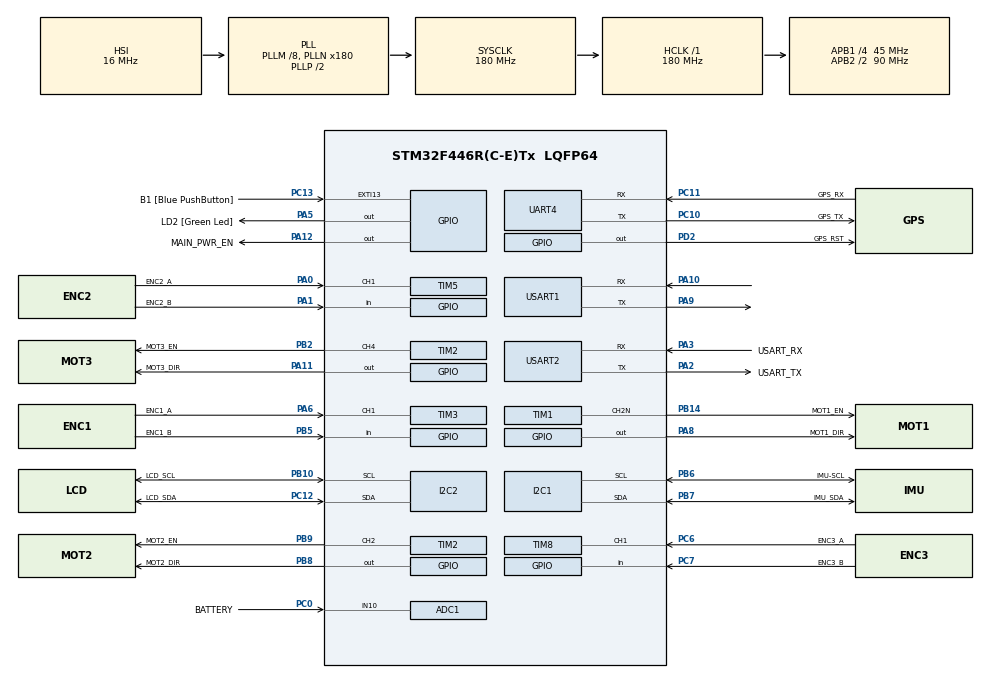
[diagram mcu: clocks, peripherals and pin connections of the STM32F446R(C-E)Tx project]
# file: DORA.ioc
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ADC1.Channel-0\#ChannelRegularConversion=ADC_CHANNEL_10
ADC1.InjNumberOfConversion=0
ADC1.NbrOfConversionFlag=1
ADC1.Rank-0\#ChannelRegularConversion=1
ADC1.SamplingTime-0\#ChannelRegularConversion=ADC_SAMPLETIME_3CYCLES
ADC1.master=1
Dma.Request0=USART2_TX
Dma.Request1=USART2_RX
Dma.Request2=USART1_RX
Dma.Request3=USART1_TX
Dma.USART1_RX.2.Direction=DMA_PERIPH_TO_MEMORY
Dma.USART1_RX.2.FIFOMode=DMA_FIFOMODE_DISABLE
Dma.USART1_RX.2.Instance=DMA2_Stream2
Dma.USART1_RX.2.MemDataAlignment=DMA_MDATAALIGN_BYTE
Dma.USART1_RX.2.MemInc=DMA_MINC_ENABLE
Dma.USART1_RX.2.Mode=DMA_CIRCULAR
Dma.USART1_RX.2.PeriphDataAlignment=DMA_PDATAALIGN_BYTE
Dma.USART1_RX.2.PeriphInc=DMA_PINC_DISABLE
Dma.USART1_RX.2.Priority=DMA_PRIORITY_LOW
Dma.USART1_TX.3.Direction=DMA_MEMORY_TO_PERIPH
Dma.USART1_TX.3.FIFOMode=DMA_FIFOMODE_DISABLE
Dma.USART1_TX.3.Instance=DMA2_Stream7
Dma.USART1_TX.3.MemDataAlignment=DMA_MDATAALIGN_BYTE
Dma.USART1_TX.3.MemInc=DMA_MINC_ENABLE
Dma.USART1_TX.3.Mode=DMA_NORMAL
Dma.USART1_TX.3.PeriphDataAlignment=DMA_PDATAALIGN_BYTE
Dma.USART1_TX.3.PeriphInc=DMA_PINC_DISABLE
Dma.USART1_TX.3.Priority=DMA_PRIORITY_LOW
Dma.USART2_RX.1.Direction=DMA_PERIPH_TO_MEMORY
Dma.USART2_RX.1.FIFOMode=DMA_FIFOMODE_DISABLE
Dma.USART2_RX.1.Instance=DMA1_Stream5
Dma.USART2_RX.1.MemDataAlignment=DMA_MDATAALIGN_BYTE
Dma.USART2_RX.1.MemInc=DMA_MINC_ENABLE
Dma.USART2_RX.1.Mode=DMA_CIRCULAR
Dma.USART2_RX.1.PeriphDataAlignment=DMA_PDATAALIGN_BYTE
Dma.USART2_RX.1.PeriphInc=DMA_PINC_DISABLE
Dma.USART2_RX.1.Priority=DMA_PRIORITY_LOW
Dma.USART2_TX.0.Direction=DMA_MEMORY_TO_PERIPH
Dma.USART2_TX.0.FIFOMode=DMA_FIFOMODE_DISABLE
Dma.USART2_TX.0.Instance=DMA1_Stream6
Dma.USART2_TX.0.MemDataAlignment=DMA_MDATAALIGN_BYTE
Dma.USART2_TX.0.MemInc=DMA_MINC_ENABLE
Dma.USART2_TX.0.Mode=DMA_NORMAL
Dma.USART2_TX.0.PeriphDataAlignment=DMA_PDATAALIGN_BYTE
Dma.USART2_TX.0.PeriphInc=DMA_PINC_DISABLE
Dma.USART2_TX.0.Priority=DMA_PRIORITY_LOW
I2C2.I2C_Mode=I2C_Fast
Mcu.Family=STM32F4
Mcu.Name=STM32F446R(C-E)Tx
Mcu.Package=LQFP64
NVIC.ADC_IRQn=true\:0\:8\:false\:false\:true\:true\:true\:true
NVIC.DMA1_Stream5_IRQn=true\:0\:0\:false\:false\:true\:false\:true\:true
NVIC.DMA1_Stream6_IRQn=true\:0\:0\:false\:false\:true\:false\:true\:true
NVIC.DMA2_Stream2_IRQn=true\:0\:0\:false\:false\:true\:false\:true\:true
NVIC.DMA2_Stream7_IRQn=true\:0\:0\:false\:false\:true\:false\:true\:true
NVIC.I2C2_EV_IRQn=true\:0\:0\:false\:false\:true\:true\:true\:true
NVIC.PriorityGroup=NVIC_PRIORITYGROUP_0
NVIC.TIM1_UP_TIM10_IRQn=true\:0\:0\:false\:false\:true\:true\:true\:true
NVIC.TIM2_IRQn=true\:0\:0\:false\:false\:true\:true\:true\:true
NVIC.TIM3_IRQn=true\:0\:0\:false\:false\:true\:true\:true\:true
NVIC.TIM5_IRQn=true\:0\:0\:false\:false\:true\:true\:true\:true
NVIC.TIM6_DAC_IRQn=true\:0\:10\:false\:false\:true\:true\:true\:true
NVIC.TIM8_CC_IRQn=true\:0\:0\:false\:false\:true\:true\:true\:true
NVIC.TIM8_UP_TIM13_IRQn=true\:0\:0\:false\:false\:true\:true\:true\:true
NVIC.UART4_IRQn=true\:0\:0\:false\:false\:true\:true\:true\:true
NVIC.USART1_IRQn=true\:0\:0\:false\:false\:true\:true\:true\:true
NVIC.USART2_IRQn=true\:0\:0\:false\:false\:true\:true\:true\:true
PA0-WKUP.GPIO_Label=ENC2_A
PA0-WKUP.Signal=S_TIM5_CH1
PA1.GPIO_Label=ENC2_B
PA1.Signal=GPIO_Input
PA10.Mode=Asynchronous
PA10.Signal=USART1_RX
PA11.GPIO_Label=MOT3_DIR
PA11.Signal=GPIO_Output
PA12.GPIO_Label=MAIN_PWR_EN
PA12.Signal=GPIO_Output
PA13.GPIO_Label=TMS
PA13.Mode=Serial_Wire
PA13.Signal=SYS_JTMS-SWDIO
PA14.GPIO_Label=TCK
PA14.Mode=Serial_Wire
PA14.Signal=SYS_JTCK-SWCLK
PA2.GPIO_Label=USART_TX
PA2.Mode=Asynchronous
PA2.Signal=USART2_TX
PA3.GPIO_Label=USART_RX
PA3.Mode=Asynchronous
PA3.Signal=USART2_RX
PA5.GPIO_Label=LD2 [Green Led]
PA5.Signal=GPIO_Output
PA6.GPIO_Label=ENC1_A
PA6.Signal=S_TIM3_CH1
PA8.GPIO_Label=MOT1_DIR
PA8.Signal=GPIO_Output
PA9.Mode=Asynchronous
PA9.Signal=USART1_TX
PB10.GPIO_Label=LCD_SCL
PB10.Mode=I2C
PB10.Signal=I2C2_SCL
PB14.GPIO_Label=MOT1_EN
PB14.Mode=PWM Generation2 CH2N
PB14.Signal=TIM1_CH2N
PB2.GPIO_Label=MOT3_EN
PB2.Signal=S_TIM2_CH4
PB3.GPIO_Label=SWO
PB3.Signal=SYS_JTDO-SWO
PB5.GPIO_Label=ENC1_B
PB5.Signal=GPIO_Input
PB6.GPIO_Label=IMU-SCL
PB6.Mode=I2C
PB6.Signal=I2C1_SCL
PB7.GPIO_Label=IMU_SDA
PB7.Mode=I2C
PB7.Signal=I2C1_SDA
PB8.GPIO_Label=MOT2_DIR
PB8.Signal=GPIO_Output
PB9.GPIO_Label=MOT2_EN
PB9.Signal=S_TIM2_CH2
PC0.GPIO_Label=BATTERY
PC0.Signal=ADCx_IN10
PC10.GPIO_Label=GPS_TX
PC10.Mode=Asynchronous
PC10.Signal=UART4_TX
PC11.GPIO_Label=GPS_RX
PC11.Mode=Asynchronous
PC11.Signal=UART4_RX
PC12.GPIO_Label=LCD_SDA
PC12.Mode=I2C
PC12.Signal=I2C2_SDA
PC13.GPIO_Label=B1 [Blue PushButton]
PC13.GPIO_ModeDefaultEXTI=GPIO_MODE_IT_FALLING
PC13.Signal=GPXTI13
PC14-OSC32_IN.Mode=LSE-External-Oscillator
PC14-OSC32_IN.Signal=RCC_OSC32_IN
PC15-OSC32_OUT.Mode=LSE-External-Oscillator
PC15-OSC32_OUT.Signal=RCC_OSC32_OUT
PC6.GPIO_Label=ENC3_A
PC6.Signal=S_TIM8_CH1
PC7.GPIO_Label=ENC3_B
PC7.Signal=GPIO_Input
PD2.GPIO_Label=GPS_RST
PD2.Signal=GPIO_Output
PH0-OSC_IN.Mode=HSE-External-Oscillator
PH0-OSC_IN.Signal=RCC_OSC_IN
PH1-OSC_OUT.Mode=HSE-External-Oscillator
PH1-OSC_OUT.Signal=RCC_OSC_OUT
ProjectManager.HeapSize=0x200
ProjectManager.StackSize=0x400
ProjectManager.TargetToolchain=STM32CubeIDE
RCC.48MHZClocksFreq_Value=84000000
RCC.AHBFreq_Value=180000000
RCC.APB1CLKDivider=RCC_HCLK_DIV4
RCC.APB1Freq_Value=45000000
RCC.APB1TimFreq_Value=90000000
RCC.APB2CLKDivider=RCC_HCLK_DIV2
RCC.APB2Freq_Value=90000000
RCC.APB2TimFreq_Value=180000000
RCC.CortexFreq_Value=180000000
RCC.FLatency-AdvancedSettings=FLASH_LATENCY_5
RCC.HCLKFreq_Value=180000000
RCC.HSE_VALUE=8000000
RCC.HSI_VALUE=16000000
RCC.PLLM=8
RCC.PLLN=180
RCC.SYSCLKFreq_VALUE=180000000
RCC.SYSCLKSource=RCC_SYSCLKSOURCE_PLLCLK
RCC.USBFreq_Value=180000000
RCC.VCOOutputFreq_Value=360000000
SH.ADCx_IN10.0=ADC1_IN10,IN10
SH.S_TIM2_CH2.0=TIM2_CH2,PWM Generation2 CH2
SH.S_TIM2_CH4.0=TIM2_CH4,PWM Generation4 CH4
SH.S_TIM3_CH1.0=TIM3_CH1,Input_Capture1_from_TI1
SH.S_TIM5_CH1.0=TIM5_CH1,Input_Capture1_from_TI1
SH.S_TIM8_CH1.0=TIM8_CH1,Input_Capture1_from_TI1
TIM1.AutoReloadPreload=TIM_AUTORELOAD_PRELOAD_ENABLE
TIM1.Channel-PWM\ Generation2\ CH2N=TIM_CHANNEL_2
TIM1.OCNIdleState_2=TIM_OCNIDLESTATE_RESET
TIM1.OCNPolarity_2=TIM_OCNPOLARITY_HIGH
TIM1.Period=1023
TIM1.Prescaler=9
TIM2.AutoReloadPreload=TIM_AUTORELOAD_PRELOAD_ENABLE
TIM2.Channel-PWM\ Generation2\ CH2=TIM_CHANNEL_2
TIM2.Channel-PWM\ Generation4\ CH4=TIM_CHANNEL_4
TIM2.Period=1023
TIM2.Prescaler=4
TIM3.Channel-Input_Capture1_from_TI1=TIM_CHANNEL_1
TIM3.ICFilter_CH1=12
TIM3.ICPolarity_CH1=TIM_INPUTCHANNELPOLARITY_BOTHEDGE
TIM3.Prescaler=3
TIM5.Channel-Input_Capture1_from_TI1=TIM_CHANNEL_1
TIM5.ICFilter_CH1=12
TIM5.ICPolarity_CH1=TIM_INPUTCHANNELPOLARITY_BOTHEDGE
TIM5.Period=65535
TIM5.Prescaler=3
TIM6.Period=999
TIM6.Prescaler=180
TIM8.Channel-Input_Capture1_from_TI1=TIM_CHANNEL_1
TIM8.ClockDivision=TIM_CLOCKDIVISION_DIV1
TIM8.ICFilter_CH1=12
TIM8.ICPolarity_CH1=TIM_INPUTCHANNELPOLARITY_BOTHEDGE
TIM8.Prescaler=7
UART4.VirtualMode=Asynchronous
USART1.VirtualMode=VM_ASYNC
USART2.VirtualMode=VM_ASYNC
VP_TIM1_VS_ClockSourceINT.Mode=Internal
VP_TIM2_VS_ClockSourceINT.Mode=Internal
VP_TIM3_VS_ClockSourceINT.Mode=Internal
VP_TIM5_VS_ClockSourceINT.Mode=Internal
VP_TIM6_VS_ClockSourceINT.Mode=Enable_Timer
VP_TIM8_VS_ClockSourceINT.Mode=Internal
board=NUCLEO-F446RE

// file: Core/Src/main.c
/* USER CODE BEGIN Header */
/**
 ******************************************************************************
 * @file           : main.c
 * @brief          : Main program body
 ******************************************************************************
 * @attention
 *
 * Copyright (c) 2023 STMicroelectronics.
 * All rights reserved.
 *
 * This software is licensed under terms that can be found in the LICENSE file
 * in the root directory of this software component.
 * If no LICENSE file comes with this software, it is provided AS-IS.
 *
 ******************************************************************************
 */
/* USER CODE END Header */
#include "main.h"

/* USER CODE BEGIN Includes */

#include "controlInterface.h"

/* USER CODE END Includes */

ADC_HandleTypeDef hadc1;

I2C_HandleTypeDef hi2c1;
I2C_HandleTypeDef hi2c2;

TIM_HandleTypeDef htim1;
TIM_HandleTypeDef htim2;
TIM_HandleTypeDef htim3;
TIM_HandleTypeDef htim5;
TIM_HandleTypeDef htim6;
TIM_HandleTypeDef htim8;

UART_HandleTypeDef huart4;
UART_HandleTypeDef huart1;
UART_HandleTypeDef huart2;
DMA_HandleTypeDef hdma_usart1_rx;
DMA_HandleTypeDef hdma_usart1_tx;
DMA_HandleTypeDef hdma_usart2_tx;
DMA_HandleTypeDef hdma_usart2_rx;

void SystemClock_Config(void);
static void MX_GPIO_Init(void);
static void MX_DMA_Init(void);
static void MX_USART2_UART_Init(void);
static void MX_ADC1_Init(void);
static void MX_I2C1_Init(void);
static void MX_I2C2_Init(void);
static void MX_TIM1_Init(void);
static void MX_TIM2_Init(void);
static void MX_TIM3_Init(void);
static void MX_TIM5_Init(void);
static void MX_TIM8_Init(void);
static void MX_UART4_Init(void);
static void MX_TIM6_Init(void);
static void MX_USART1_UART_Init(void);

int main(void) {

    /* MCU Configuration--------------------------------------------------------*/

    /* Reset of all peripherals, Initializes the Flash interface and the Systick. */
    HAL_Init();

    /* Configure the system clock */
    SystemClock_Config();

    /* Initialize all configured peripherals */
    MX_GPIO_Init();
    MX_DMA_Init();
    MX_USART2_UART_Init();
    MX_ADC1_Init();
    MX_I2C1_Init();
    MX_I2C2_Init();
    MX_TIM1_Init();
    MX_TIM2_Init();
    MX_TIM3_Init();
    MX_TIM5_Init();
    MX_TIM8_Init();
    MX_UART4_Init();
    MX_TIM6_Init();
    MX_USART1_UART_Init();
    /* USER CODE BEGIN 2 */

    startControl();

    /* USER CODE END 2 */

    /* Infinite loop */
    while (1) {

    }
}

void SystemClock_Config(void) {
    RCC_OscInitTypeDef RCC_OscInitStruct = { 0 };
    RCC_ClkInitTypeDef RCC_ClkInitStruct = { 0 };

    /** Configure the main internal regulator output voltage
     */
    __HAL_RCC_PWR_CLK_ENABLE();
    __HAL_PWR_VOLTAGESCALING_CONFIG(PWR_REGULATOR_VOLTAGE_SCALE1);

    /** Initializes the RCC Oscillators according to the specified parameters
     * in the RCC_OscInitTypeDef structure.
     */
    RCC_OscInitStruct.OscillatorType = RCC_OSCILLATORTYPE_HSI;
    RCC_OscInitStruct.HSIState = RCC_HSI_ON;
    RCC_OscInitStruct.HSICalibrationValue = RCC_HSICALIBRATION_DEFAULT;
    RCC_OscInitStruct.PLL.PLLState = RCC_PLL_ON;
    RCC_OscInitStruct.PLL.PLLSource = RCC_PLLSOURCE_HSI;
    RCC_OscInitStruct.PLL.PLLM = 8;
    RCC_OscInitStruct.PLL.PLLN = 180;
    RCC_OscInitStruct.PLL.PLLP = RCC_PLLP_DIV2;
    RCC_OscInitStruct.PLL.PLLQ = 2;
    RCC_OscInitStruct.PLL.PLLR = 2;
    if (HAL_RCC_OscConfig(&RCC_OscInitStruct) != HAL_OK) {
        Error_Handler();
    }

    /** Activate the Over-Drive mode
     */
    if (HAL_PWREx_EnableOverDrive() != HAL_OK) {
        Error_Handler();
    }

    /** Initializes the CPU, AHB and APB buses clocks
     */
    RCC_ClkInitStruct.ClockType = RCC_CLOCKTYPE_HCLK | RCC_CLOCKTYPE_SYSCLK | RCC_CLOCKTYPE_PCLK1 | RCC_CLOCKTYPE_PCLK2;
    RCC_ClkInitStruct.SYSCLKSource = RCC_SYSCLKSOURCE_PLLCLK;
    RCC_ClkInitStruct.AHBCLKDivider = RCC_SYSCLK_DIV1;
    RCC_ClkInitStruct.APB1CLKDivider = RCC_HCLK_DIV4;
    RCC_ClkInitStruct.APB2CLKDivider = RCC_HCLK_DIV2;

    if (HAL_RCC_ClockConfig(&RCC_ClkInitStruct, FLASH_LATENCY_5) != HAL_OK) {
        Error_Handler();
    }
}

static void MX_ADC1_Init(void) {

    ADC_ChannelConfTypeDef sConfig = { 0 };

    /** Configure the global features of the ADC (Clock, Resolution, Data Alignment and number of conversion)
     */
    hadc1.Instance = ADC1;
    hadc1.Init.ClockPrescaler = ADC_CLOCK_SYNC_PCLK_DIV4;
    hadc1.Init.Resolution = ADC_RESOLUTION_12B;
    hadc1.Init.ScanConvMode = DISABLE;
    hadc1.Init.ContinuousConvMode = DISABLE;
    hadc1.Init.DiscontinuousConvMode = DISABLE;
    hadc1.Init.ExternalTrigConvEdge = ADC_EXTERNALTRIGCONVEDGE_NONE;
    hadc1.Init.ExternalTrigConv = ADC_SOFTWARE_START;
    hadc1.Init.DataAlign = ADC_DATAALIGN_RIGHT;
    hadc1.Init.NbrOfConversion = 1;
    hadc1.Init.DMAContinuousRequests = DISABLE;
    hadc1.Init.EOCSelection = ADC_EOC_SINGLE_CONV;
    if (HAL_ADC_Init(&hadc1) != HAL_OK) {
        Error_Handler();
    }

    /** Configure for the selected ADC regular channel its corresponding rank in the sequencer and its sample time.
     */
    sConfig.Channel = ADC_CHANNEL_10;
    sConfig.Rank = 1;
    sConfig.SamplingTime = ADC_SAMPLETIME_3CYCLES;
    if (HAL_ADC_ConfigChannel(&hadc1, &sConfig) != HAL_OK) {
        Error_Handler();
    }
}

static void MX_I2C1_Init(void) {

    hi2c1.Instance = I2C1;
    hi2c1.Init.ClockSpeed = 100000;
    hi2c1.Init.DutyCycle = I2C_DUTYCYCLE_2;
    hi2c1.Init.OwnAddress1 = 0;
    hi2c1.Init.AddressingMode = I2C_ADDRESSINGMODE_7BIT;
    hi2c1.Init.DualAddressMode = I2C_DUALADDRESS_DISABLE;
    hi2c1.Init.OwnAddress2 = 0;
    hi2c1.Init.GeneralCallMode = I2C_GENERALCALL_DISABLE;
    hi2c1.Init.NoStretchMode = I2C_NOSTRETCH_DISABLE;
    if (HAL_I2C_Init(&hi2c1) != HAL_OK) {
        Error_Handler();
    }
}

static void MX_I2C2_Init(void) {

    hi2c2.Instance = I2C2;
    hi2c2.Init.ClockSpeed = 400000;
    hi2c2.Init.DutyCycle = I2C_DUTYCYCLE_2;
    hi2c2.Init.OwnAddress1 = 0;
    hi2c2.Init.AddressingMode = I2C_ADDRESSINGMODE_7BIT;
    hi2c2.Init.DualAddressMode = I2C_DUALADDRESS_DISABLE;
    hi2c2.Init.OwnAddress2 = 0;
    hi2c2.Init.GeneralCallMode = I2C_GENERALCALL_DISABLE;
    hi2c2.Init.NoStretchMode = I2C_NOSTRETCH_DISABLE;
    if (HAL_I2C_Init(&hi2c2) != HAL_OK) {
        Error_Handler();
    }
}

static void MX_TIM1_Init(void) {

    TIM_ClockConfigTypeDef sClockSourceConfig = { 0 };
    TIM_MasterConfigTypeDef sMasterConfig = { 0 };
    TIM_OC_InitTypeDef sConfigOC = { 0 };
    TIM_BreakDeadTimeConfigTypeDef sBreakDeadTimeConfig = { 0 };

    htim1.Instance = TIM1;
    htim1.Init.Prescaler = 9;
    htim1.Init.CounterMode = TIM_COUNTERMODE_UP;
    htim1.Init.Period = 1023;
    htim1.Init.ClockDivision = TIM_CLOCKDIVISION_DIV1;
    htim1.Init.RepetitionCounter = 0;
    htim1.Init.AutoReloadPreload = TIM_AUTORELOAD_PRELOAD_ENABLE;
    if (HAL_TIM_Base_Init(&htim1) != HAL_OK) {
        Error_Handler();
    }
    sClockSourceConfig.ClockSource = TIM_CLOCKSOURCE_INTERNAL;
    if (HAL_TIM_ConfigClockSource(&htim1, &sClockSourceConfig) != HAL_OK) {
        Error_Handler();
    }
    if (HAL_TIM_PWM_Init(&htim1) != HAL_OK) {
        Error_Handler();
    }
    sMasterConfig.MasterOutputTrigger = TIM_TRGO_RESET;
    sMasterConfig.MasterSlaveMode = TIM_MASTERSLAVEMODE_DISABLE;
    if (HAL_TIMEx_MasterConfigSynchronization(&htim1, &sMasterConfig) != HAL_OK) {
        Error_Handler();
    }
    sConfigOC.OCMode = TIM_OCMODE_PWM1;
    sConfigOC.Pulse = 0;
    sConfigOC.OCPolarity = TIM_OCPOLARITY_HIGH;
    sConfigOC.OCNPolarity = TIM_OCNPOLARITY_HIGH;
    sConfigOC.OCFastMode = TIM_OCFAST_DISABLE;
    sConfigOC.OCIdleState = TIM_OCIDLESTATE_RESET;
    sConfigOC.OCNIdleState = TIM_OCNIDLESTATE_RESET;
    if (HAL_TIM_PWM_ConfigChannel(&htim1, &sConfigOC, TIM_CHANNEL_2) != HAL_OK) {
        Error_Handler();
    }
    sBreakDeadTimeConfig.OffStateRunMode = TIM_OSSR_DISABLE;
    sBreakDeadTimeConfig.OffStateIDLEMode = TIM_OSSI_DISABLE;
    sBreakDeadTimeConfig.LockLevel = TIM_LOCKLEVEL_OFF;
    sBreakDeadTimeConfig.DeadTime = 0;
    sBreakDeadTimeConfig.BreakState = TIM_BREAK_DISABLE;
    sBreakDeadTimeConfig.BreakPolarity = TIM_BREAKPOLARITY_HIGH;
    sBreakDeadTimeConfig.AutomaticOutput = TIM_AUTOMATICOUTPUT_DISABLE;
    if (HAL_TIMEx_ConfigBreakDeadTime(&htim1, &sBreakDeadTimeConfig) != HAL_OK) {
        Error_Handler();
    }
    HAL_TIM_MspPostInit(&htim1);
}

static void MX_TIM2_Init(void) {

    TIM_ClockConfigTypeDef sClockSourceConfig = { 0 };
    TIM_MasterConfigTypeDef sMasterConfig = { 0 };
    TIM_OC_InitTypeDef sConfigOC = { 0 };

    htim2.Instance = TIM2;
    htim2.Init.Prescaler = 4;
    htim2.Init.CounterMode = TIM_COUNTERMODE_UP;
    htim2.Init.Period = 1023;
    htim2.Init.ClockDivision = TIM_CLOCKDIVISION_DIV1;
    htim2.Init.AutoReloadPreload = TIM_AUTORELOAD_PRELOAD_ENABLE;
    if (HAL_TIM_Base_Init(&htim2) != HAL_OK) {
        Error_Handler();
    }
    sClockSourceConfig.ClockSource = TIM_CLOCKSOURCE_INTERNAL;
    if (HAL_TIM_ConfigClockSource(&htim2, &sClockSourceConfig) != HAL_OK) {
        Error_Handler();
    }
    if (HAL_TIM_PWM_Init(&htim2) != HAL_OK) {
        Error_Handler();
    }
    sMasterConfig.MasterOutputTrigger = TIM_TRGO_RESET;
    sMasterConfig.MasterSlaveMode = TIM_MASTERSLAVEMODE_DISABLE;
    if (HAL_TIMEx_MasterConfigSynchronization(&htim2, &sMasterConfig) != HAL_OK) {
        Error_Handler();
    }
    sConfigOC.OCMode = TIM_OCMODE_PWM1;
    sConfigOC.Pulse = 0;
    sConfigOC.OCPolarity = TIM_OCPOLARITY_HIGH;
    sConfigOC.OCFastMode = TIM_OCFAST_DISABLE;
    if (HAL_TIM_PWM_ConfigChannel(&htim2, &sConfigOC, TIM_CHANNEL_2) != HAL_OK) {
        Error_Handler();
    }
    if (HAL_TIM_PWM_ConfigChannel(&htim2, &sConfigOC, TIM_CHANNEL_4) != HAL_OK) {
        Error_Handler();
    }
    HAL_TIM_MspPostInit(&htim2);
}

static void MX_TIM3_Init(void) {

    TIM_ClockConfigTypeDef sClockSourceConfig = { 0 };
    TIM_MasterConfigTypeDef sMasterConfig = { 0 };
    TIM_IC_InitTypeDef sConfigIC = { 0 };

    htim3.Instance = TIM3;
    htim3.Init.Prescaler = 3;
    htim3.Init.CounterMode = TIM_COUNTERMODE_UP;
    htim3.Init.Period = 65535;
    htim3.Init.ClockDivision = TIM_CLOCKDIVISION_DIV1;
    htim3.Init.AutoReloadPreload = TIM_AUTORELOAD_PRELOAD_DISABLE;
    if (HAL_TIM_Base_Init(&htim3) != HAL_OK) {
        Error_Handler();
    }
    sClockSourceConfig.ClockSource = TIM_CLOCKSOURCE_INTERNAL;
    if (HAL_TIM_ConfigClockSource(&htim3, &sClockSourceConfig) != HAL_OK) {
        Error_Handler();
    }
    if (HAL_TIM_IC_Init(&htim3) != HAL_OK) {
        Error_Handler();
    }
    sMasterConfig.MasterOutputTrigger = TIM_TRGO_RESET;
    sMasterConfig.MasterSlaveMode = TIM_MASTERSLAVEMODE_DISABLE;
    if (HAL_TIMEx_MasterConfigSynchronization(&htim3, &sMasterConfig) != HAL_OK) {
        Error_Handler();
    }
    sConfigIC.ICPolarity = TIM_INPUTCHANNELPOLARITY_BOTHEDGE;
    sConfigIC.ICSelection = TIM_ICSELECTION_DIRECTTI;
    sConfigIC.ICPrescaler = TIM_ICPSC_DIV1;
    sConfigIC.ICFilter = 12;
    if (HAL_TIM_IC_ConfigChannel(&htim3, &sConfigIC, TIM_CHANNEL_1) != HAL_OK) {
        Error_Handler();
    }
}

static void MX_TIM5_Init(void) {

    TIM_ClockConfigTypeDef sClockSourceConfig = { 0 };
    TIM_MasterConfigTypeDef sMasterConfig = { 0 };
    TIM_IC_InitTypeDef sConfigIC = { 0 };

    htim5.Instance = TIM5;
    htim5.Init.Prescaler = 3;
    htim5.Init.CounterMode = TIM_COUNTERMODE_UP;
    htim5.Init.Period = 65535;
    htim5.Init.ClockDivision = TIM_CLOCKDIVISION_DIV1;
    htim5.Init.AutoReloadPreload = TIM_AUTORELOAD_PRELOAD_DISABLE;
    if (HAL_TIM_Base_Init(&htim5) != HAL_OK) {
        Error_Handler();
    }
    sClockSourceConfig.ClockSource = TIM_CLOCKSOURCE_INTERNAL;
    if (HAL_TIM_ConfigClockSource(&htim5, &sClockSourceConfig) != HAL_OK) {
        Error_Handler();
    }
    if (HAL_TIM_IC_Init(&htim5) != HAL_OK) {
        Error_Handler();
    }
    sMasterConfig.MasterOutputTrigger = TIM_TRGO_RESET;
    sMasterConfig.MasterSlaveMode = TIM_MASTERSLAVEMODE_DISABLE;
    if (HAL_TIMEx_MasterConfigSynchronization(&htim5, &sMasterConfig) != HAL_OK) {
        Error_Handler();
    }
    sConfigIC.ICPolarity = TIM_INPUTCHANNELPOLARITY_BOTHEDGE;
    sConfigIC.ICSelection = TIM_ICSELECTION_DIRECTTI;
    sConfigIC.ICPrescaler = TIM_ICPSC_DIV1;
    sConfigIC.ICFilter = 12;
    if (HAL_TIM_IC_ConfigChannel(&htim5, &sConfigIC, TIM_CHANNEL_1) != HAL_OK) {
        Error_Handler();
    }
}

static void MX_TIM6_Init(void) {

    TIM_MasterConfigTypeDef sMasterConfig = { 0 };

    htim6.Instance = TIM6;
    htim6.Init.Prescaler = 180;
    htim6.Init.CounterMode = TIM_COUNTERMODE_UP;
    htim6.Init.Period = 999;
    htim6.Init.AutoReloadPreload = TIM_AUTORELOAD_PRELOAD_DISABLE;
    if (HAL_TIM_Base_Init(&htim6) != HAL_OK) {
        Error_Handler();
    }
    sMasterConfig.MasterOutputTrigger = TIM_TRGO_RESET;
    sMasterConfig.MasterSlaveMode = TIM_MASTERSLAVEMODE_DISABLE;
    if (HAL_TIMEx_MasterConfigSynchronization(&htim6, &sMasterConfig) != HAL_OK) {
        Error_Handler();
    }
}

static void MX_TIM8_Init(void) {

    TIM_ClockConfigTypeDef sClockSourceConfig = { 0 };
    TIM_MasterConfigTypeDef sMasterConfig = { 0 };
    TIM_IC_InitTypeDef sConfigIC = { 0 };

    htim8.Instance = TIM8;
    htim8.Init.Prescaler = 7;
    htim8.Init.CounterMode = TIM_COUNTERMODE_UP;
    htim8.Init.Period = 65535;
    htim8.Init.ClockDivision = TIM_CLOCKDIVISION_DIV1;
    htim8.Init.RepetitionCounter = 0;
    htim8.Init.AutoReloadPreload = TIM_AUTORELOAD_PRELOAD_DISABLE;
    if (HAL_TIM_Base_Init(&htim8) != HAL_OK) {
        Error_Handler();
    }
    sClockSourceConfig.ClockSource = TIM_CLOCKSOURCE_INTERNAL;
    if (HAL_TIM_ConfigClockSource(&htim8, &sClockSourceConfig) != HAL_OK) {
        Error_Handler();
    }
    if (HAL_TIM_IC_Init(&htim8) != HAL_OK) {
        Error_Handler();
    }
    sMasterConfig.MasterOutputTrigger = TIM_TRGO_RESET;
    sMasterConfig.MasterSlaveMode = TIM_MASTERSLAVEMODE_DISABLE;
    if (HAL_TIMEx_MasterConfigSynchronization(&htim8, &sMasterConfig) != HAL_OK) {
        Error_Handler();
    }
    sConfigIC.ICPolarity = TIM_INPUTCHANNELPOLARITY_BOTHEDGE;
    sConfigIC.ICSelection = TIM_ICSELECTION_DIRECTTI;
    sConfigIC.ICPrescaler = TIM_ICPSC_DIV1;
    sConfigIC.ICFilter = 12;
    if (HAL_TIM_IC_ConfigChannel(&htim8, &sConfigIC, TIM_CHANNEL_1) != HAL_OK) {
        Error_Handler();
    }
}

static void MX_UART4_Init(void) {

    huart4.Instance = UART4;
    huart4.Init.BaudRate = 115200;
    huart4.Init.WordLength = UART_WORDLENGTH_8B;
    huart4.Init.StopBits = UART_STOPBITS_1;
    huart4.Init.Parity = UART_PARITY_NONE;
    huart4.Init.Mode = UART_MODE_TX_RX;
    huart4.Init.HwFlowCtl = UART_HWCONTROL_NONE;
    huart4.Init.OverSampling = UART_OVERSAMPLING_16;
    if (HAL_UART_Init(&huart4) != HAL_OK) {
        Error_Handler();
    }
}

static void MX_USART1_UART_Init(void) {

    huart1.Instance = USART1;
    huart1.Init.BaudRate = 115200;
    huart1.Init.WordLength = UART_WORDLENGTH_8B;
    huart1.Init.StopBits = UART_STOPBITS_1;
    huart1.Init.Parity = UART_PARITY_NONE;
    huart1.Init.Mode = UART_MODE_TX_RX;
    huart1.Init.HwFlowCtl = UART_HWCONTROL_NONE;
    huart1.Init.OverSampling = UART_OVERSAMPLING_16;
    if (HAL_UART_Init(&huart1) != HAL_OK) {
        Error_Handler();
    }
}

static void MX_USART2_UART_Init(void) {

    huart2.Instance = USART2;
    huart2.Init.BaudRate = 115200;
    huart2.Init.WordLength = UART_WORDLENGTH_8B;
    huart2.Init.StopBits = UART_STOPBITS_1;
    huart2.Init.Parity = UART_PARITY_NONE;
    huart2.Init.Mode = UART_MODE_TX_RX;
    huart2.Init.HwFlowCtl = UART_HWCONTROL_NONE;
    huart2.Init.OverSampling = UART_OVERSAMPLING_16;
    if (HAL_UART_Init(&huart2) != HAL_OK) {
        Error_Handler();
    }
}

static void MX_DMA_Init(void) {

    /* DMA controller clock enable */
    __HAL_RCC_DMA1_CLK_ENABLE();
    __HAL_RCC_DMA2_CLK_ENABLE();

    /* DMA interrupt init */
    /* DMA1_Stream5_IRQn interrupt configuration */
    HAL_NVIC_SetPriority(DMA1_Stream5_IRQn, 0, 0);
    HAL_NVIC_EnableIRQ(DMA1_Stream5_IRQn);
    /* DMA1_Stream6_IRQn interrupt configuration */
    HAL_NVIC_SetPriority(DMA1_Stream6_IRQn, 0, 0);
    HAL_NVIC_EnableIRQ(DMA1_Stream6_IRQn);
    /* DMA2_Stream2_IRQn interrupt configuration */
    HAL_NVIC_SetPriority(DMA2_Stream2_IRQn, 0, 0);
    HAL_NVIC_EnableIRQ(DMA2_Stream2_IRQn);
    /* DMA2_Stream7_IRQn interrupt configuration */
    HAL_NVIC_SetPriority(DMA2_Stream7_IRQn, 0, 0);
    HAL_NVIC_EnableIRQ(DMA2_Stream7_IRQn);
}

static void MX_GPIO_Init(void) {
    GPIO_InitTypeDef GPIO_InitStruct = { 0 };

    /* GPIO Ports Clock Enable */
    __HAL_RCC_GPIOC_CLK_ENABLE();
    __HAL_RCC_GPIOH_CLK_ENABLE();
    __HAL_RCC_GPIOA_CLK_ENABLE();
    __HAL_RCC_GPIOB_CLK_ENABLE();
    __HAL_RCC_GPIOD_CLK_ENABLE();

    /*Configure GPIO pin Output Level */
    HAL_GPIO_WritePin(GPIOA, LD2_Pin | MOT1_DIR_Pin | MOT3_DIR_Pin | MAIN_PWR_EN_Pin, GPIO_PIN_RESET);

    /*Configure GPIO pin Output Level */
    HAL_GPIO_WritePin(GPS_RST_GPIO_Port, GPS_RST_Pin, GPIO_PIN_RESET);

    /*Configure GPIO pin Output Level */
    HAL_GPIO_WritePin(MOT2_DIR_GPIO_Port, MOT2_DIR_Pin, GPIO_PIN_RESET);

    /*Configure GPIO pin : B1_Pin */
    GPIO_InitStruct.Pin = B1_Pin;
    GPIO_InitStruct.Mode = GPIO_MODE_IT_FALLING;
    GPIO_InitStruct.Pull = GPIO_NOPULL;
    HAL_GPIO_Init(B1_GPIO_Port, &GPIO_InitStruct);

    /*Configure GPIO pin : ENC2_B_Pin */
    GPIO_InitStruct.Pin = ENC2_B_Pin;
    GPIO_InitStruct.Mode = GPIO_MODE_INPUT;
    GPIO_InitStruct.Pull = GPIO_NOPULL;
    HAL_GPIO_Init(ENC2_B_GPIO_Port, &GPIO_InitStruct);

    /*Configure GPIO pins : LD2_Pin MOT1_DIR_Pin MOT3_DIR_Pin MAIN_PWR_EN_Pin */
    GPIO_InitStruct.Pin = LD2_Pin | MOT1_DIR_Pin | MOT3_DIR_Pin | MAIN_PWR_EN_Pin;
    GPIO_InitStruct.Mode = GPIO_MODE_OUTPUT_PP;
    GPIO_InitStruct.Pull = GPIO_NOPULL;
    GPIO_InitStruct.Speed = GPIO_SPEED_FREQ_LOW;
    HAL_GPIO_Init(GPIOA, &GPIO_InitStruct);

    /*Configure GPIO pin : ENC3_B_Pin */
    GPIO_InitStruct.Pin = ENC3_B_Pin;
    GPIO_InitStruct.Mode = GPIO_MODE_INPUT;
    GPIO_InitStruct.Pull = GPIO_NOPULL;
    HAL_GPIO_Init(ENC3_B_GPIO_Port, &GPIO_InitStruct);

    /*Configure GPIO pin : GPS_RST_Pin */
    GPIO_InitStruct.Pin = GPS_RST_Pin;
    GPIO_InitStruct.Mode = GPIO_MODE_OUTPUT_PP;
    GPIO_InitStruct.Pull = GPIO_NOPULL;
    GPIO_InitStruct.Speed = GPIO_SPEED_FREQ_LOW;
    HAL_GPIO_Init(GPS_RST_GPIO_Port, &GPIO_InitStruct);

    /*Configure GPIO pin : ENC1_B_Pin */
    GPIO_InitStruct.Pin = ENC1_B_Pin;
    GPIO_InitStruct.Mode = GPIO_MODE_INPUT;
    GPIO_InitStruct.Pull = GPIO_NOPULL;
    HAL_GPIO_Init(ENC1_B_GPIO_Port, &GPIO_InitStruct);

    /*Configure GPIO pin : MOT2_DIR_Pin */
    GPIO_InitStruct.Pin = MOT2_DIR_Pin;
    GPIO_InitStruct.Mode = GPIO_MODE_OUTPUT_PP;
    GPIO_InitStruct.Pull = GPIO_NOPULL;
    GPIO_InitStruct.Speed = GPIO_SPEED_FREQ_LOW;
    HAL_GPIO_Init(MOT2_DIR_GPIO_Port, &GPIO_InitStruct);
}

void Error_Handler(void) {
    __disable_irq();
    while (1) {
    }
}
